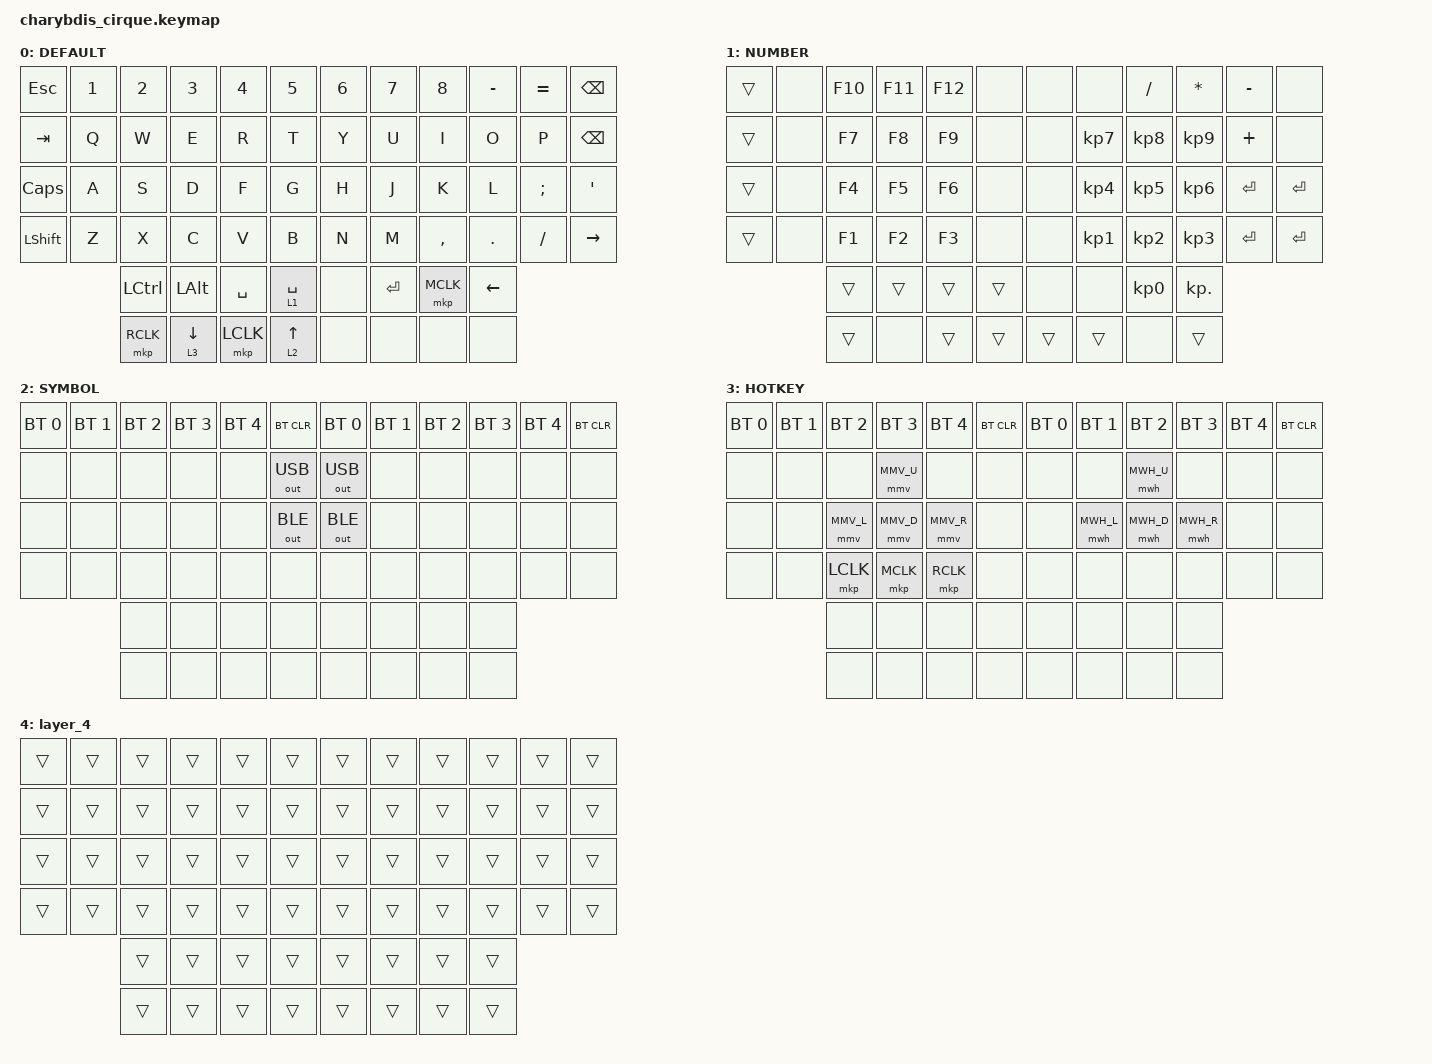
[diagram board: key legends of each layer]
#include <dt-bindings/zmk/mouse.h>
#include <behaviors.dtsi>
#include <dt-bindings/zmk/bt.h>
#include <dt-bindings/zmk/keys.h>
#include <dt-bindings/zmk/outputs.h>

// mouse move settings

#define MMV_U MOVE_VERT(-650)
#define MMV_D MOVE_VERT(650)
#define MMV_L MOVE_HOR(-650)
#define MMV_R MOVE_HOR(650)

&mmv {
    time-to-max-speed-ms = <500>;
    acceleration-exponent = <1>;
};

// mouse wheel settings

#define MWH_U SCROLL_VERT(15)
#define MWH_D SCROLL_VERT(-15)
#define MWH_L SCROLL_HOR(-15)
#define MWH_R SCROLL_HOR(15)

&mwh {
    time-to-max-speed-ms = <2000>;
    acceleration-exponent = <0>;
};

#define DEFAULT 0
#define NUMBER  1
#define SYMBOL  2
#define HOTKEY  3

#define AS(keycode) &as LS(keycode) keycode

/ {
    behaviors {
        td0: tap_dance_0 {
            compatible = "zmk,behavior-tap-dance";
            label = "TAP_DANCE_0";
            #binding-cells = <0>;
            tapping-term-ms = <200>;
            bindings = <&kp ESC>, <&kp TAB>;
        };
    };

    behaviors {
        as: auto_shift {
            compatible = "zmk,behavior-hold-tap";
            label = "AUTO_SHIFT";
            #binding-cells = <2>;
            tapping-term-ms = <200>;
            quick-tap-ms = <0>;
            flavor = "tap-preferred";
            bindings = <&kp>, <&kp>;
        };

        modcp: mod_copy {
            compatible = "zmk,behavior-mod-morph";
            label = "MOD_COPY";
            #binding-cells = <0>;
            bindings = <&as LS(C) C>, <&kp C>;

            mods = <(LGUI | RGUI)>;
        };
    };

    macros {
        macro_phone: macro_phone {
            // 1351

            label = "MACRO_PHONE";
            compatible = "zmk,behavior-macro";
            #binding-cells = <0>;
            bindings = <&kp N1 &kp N3 &kp N5 &kp N1>;
        };
    };

    combos {
        compatible = "zmk,combos";

        yinliang {
            bindings = <&kp C_VOL_UP>;
            key-positions = <48 49>;
        };

        yinliang- {
            bindings = <&kp C_VOL_DN>;
            key-positions = <54 55>;
        };
    };

    keymap {
        compatible = "zmk,keymap";

        default_layer {
            label = "DEFAULT";
            bindings = <
&kp ESC    &kp N1  &kp N2     &kp N3        &kp N4     &kp N5          &kp N6  &kp N7   &kp N8     &kp MINUS       &kp EQUAL  &kp BACKSPACE
&kp TAB    &kp Q   &kp W      &kp E         &kp R      &kp T           &kp Y   &kp U    &kp I      &kp O           &kp P      &kp BACKSPACE
&kp CLCK   &kp A   &kp S      &kp D         &kp F      &kp G           &kp H   &kp J    &kp K      &kp L           &kp SEMI   &kp SQT
&kp LSHFT  &kp Z   &kp X      &kp C         &kp V      &kp B           &kp N   &kp M    &kp COMMA  &kp DOT         &kp FSLH   &kp RIGHT_ARROW
                   &kp LCTRL  &kp LEFT_ALT  &kp SPACE  &lt 1 SPACE     &none   &kp RET  &mkp MCLK  &kp LEFT_ARROW
                   &mkp RCLK  &lt 3 DOWN    &mkp LCLK  &lt 2 UP_ARROW  &none   &none    &none      &none
            >;

            sensor-bindings = <&inc_dec_kp C_VOL_UP C_VOL_DN &inc_dec_kp RIGHT LEFT>;
            trackball-bindings = <&tmv>;
        };

        number_layer {
            label = "NUMBER";
            bindings = <
&trans  &none  &kp F10  &kp F11  &kp F12  &none   &none   &none      &kp FSLH   &kp STAR    &kp MINUS  &none
&trans  &none  &kp F7   &kp F8   &kp F9   &none   &none   &kp KP_N7  &kp KP_N8  &kp KP_N9   &kp PLUS   &none
&trans  &none  &kp F4   &kp F5   &kp F6   &none   &none   &kp KP_N4  &kp KP_N5  &kp KP_N6   &kp ENTER  &kp RET
&trans  &none  &kp F1   &kp F2   &kp F3   &none   &none   &kp KP_N1  &kp KP_N2  &kp KP_N3   &kp ENTER  &kp ENTER
               &trans   &trans   &trans   &trans  &none   &none      &kp KP_N0  &kp KP_DOT
               &trans   &none    &trans   &trans  &trans  &trans     &none      &trans
            >;

            trackball-bindings = <&tsl>;
            sensor-bindings = <&inc_dec_kp C_VOL_UP C_VOL_DN &inc_dec_kp RIGHT LEFT>;
        };

        symbol_layer {
            label = "SYMBOL";
            bindings = <
&bt BT_SEL 0  &bt BT_SEL 1  &bt BT_SEL 2  &bt BT_SEL 3  &bt BT_SEL 4  &bt BT_CLR    &bt BT_SEL 0  &bt BT_SEL 1  &bt BT_SEL 2  &bt BT_SEL 3  &bt BT_SEL 4  &bt BT_CLR
&none         &none         &none         &none         &none         &out OUT_USB  &out OUT_USB  &none         &none         &none         &none         &none
&none         &none         &none         &none         &none         &out OUT_BLE  &out OUT_BLE  &none         &none         &none         &none         &none
&none         &none         &none         &none         &none         &none         &none         &none         &none         &none         &none         &none
                            &none         &none         &none         &none         &none         &none         &none         &none
                            &none         &none         &none         &none         &none         &none         &none         &none
            >;

            trackball-bindings = <&tmv_fine>;
            sensor-bindings = <&inc_dec_kp C_VOL_UP C_VOL_DN &inc_dec_kp RIGHT LEFT>;
        };

        hotkey_layer {
            label = "HOTKEY";
            bindings = <
&bt BT_SEL 0  &bt BT_SEL 1  &bt BT_SEL 2  &bt BT_SEL 3  &bt BT_SEL 4  &bt BT_CLR  &bt BT_SEL 0  &bt BT_SEL 1  &bt BT_SEL 2  &bt BT_SEL 3  &bt BT_SEL 4  &bt BT_CLR
&none         &none         &none         &mmv MMV_U    &none         &none       &none         &none         &mwh MWH_U    &none         &none         &none
&none         &none         &mmv MMV_L    &mmv MMV_D    &mmv MMV_R    &none       &none         &mwh MWH_L    &mwh MWH_D    &mwh MWH_R    &none         &none
&none         &none         &mkp LCLK     &mkp MCLK     &mkp RCLK     &none       &none         &none         &none         &none         &none         &none
                            &none         &none         &none         &none       &none         &none         &none         &none
                            &none         &none         &none         &none       &none         &none         &none         &none
            >;

            trackball-bindings = <&tmv_x>;
            sensor-bindings = <&inc_dec_kp C_VOL_UP C_VOL_DN &inc_dec_kp RIGHT LEFT>;
        };

        layer_4 {
            bindings = <
&trans  &trans  &trans  &trans  &trans  &trans  &trans  &trans  &trans  &trans  &trans  &trans
&trans  &trans  &trans  &trans  &trans  &trans  &trans  &trans  &trans  &trans  &trans  &trans
&trans  &trans  &trans  &trans  &trans  &trans  &trans  &trans  &trans  &trans  &trans  &trans
&trans  &trans  &trans  &trans  &trans  &trans  &trans  &trans  &trans  &trans  &trans  &trans
                &trans  &trans  &trans  &trans  &trans  &trans  &trans  &trans
                &trans  &trans  &trans  &trans  &trans  &trans  &trans  &trans
            >;
        };
    };
};
